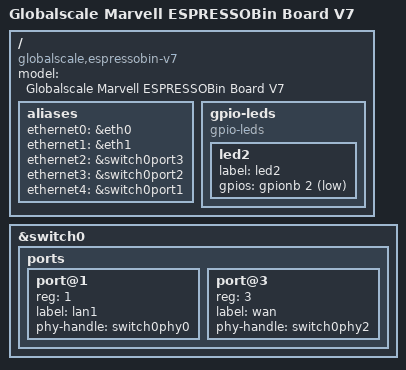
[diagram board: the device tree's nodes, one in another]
// SPDX-License-Identifier: (GPL-2.0+ OR MIT)
/*
 * Device Tree file for Globalscale Marvell ESPRESSOBin Board V7
 * Copyright (C) 2018 Marvell
 *
 * Romain Perier <romain.perier@free-electrons.com>
 * Konstantin Porotchkin <kostap@marvell.com>
 *
 */
/*
 * Schematic available at http://wiki.espressobin.net/tiki-download_file.php?fileId=200
 */

/dts-v1/;

#include "armada-3720-espressobin.dtsi"

/ {
	model = "Globalscale Marvell ESPRESSOBin Board V7";
	compatible = "globalscale,espressobin-v7", "globalscale,espressobin",
		     "marvell,armada3720", "marvell,armada3710";

	aliases {
		ethernet0 = &eth0;
		ethernet1 = &eth1;
		/* for dsa slave device */
		ethernet2 = &switch0port3;
		ethernet3 = &switch0port2;
		ethernet4 = &switch0port1;
	};

	gpio-leds {
		compatible = "gpio-leds";

		led2 {
			label = "led2";
			gpios = <&gpionb 2 GPIO_ACTIVE_LOW>;
		};
	};
};

&switch0 {
	ports {
		port@1 {
			reg = <1>;
			label = "lan1";
			phy-handle = <&switch0phy0>;
		};

		port@3 {
			reg = <3>;
			label = "wan";
			phy-handle = <&switch0phy2>;
		};
	};
};
